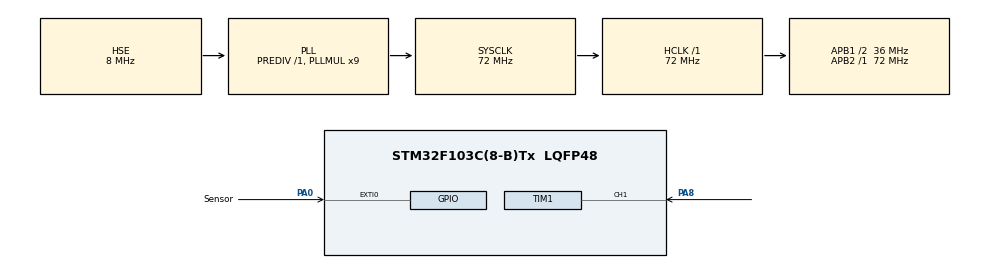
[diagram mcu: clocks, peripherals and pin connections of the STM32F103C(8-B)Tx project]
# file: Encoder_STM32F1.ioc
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Mcu.Family=STM32F1
Mcu.Name=STM32F103C(8-B)Tx
Mcu.Package=LQFP48
NVIC.EXTI0_IRQn=true\:0\:0\:true\:false\:true\:true\:true
NVIC.PriorityGroup=NVIC_PRIORITYGROUP_4
NVIC.TIM3_IRQn=true\:0\:0\:true\:false\:true\:true\:true
PA0-WKUP.GPIO_Label=Sensor
PA0-WKUP.GPIO_ModeDefaultEXTI=GPIO_MODE_IT_FALLING
PA0-WKUP.GPIO_PuPd=GPIO_PULLUP
PA0-WKUP.Signal=GPXTI0
PA13.Mode=Serial_Wire
PA13.Signal=SYS_JTMS-SWDIO
PA14.Mode=Serial_Wire
PA14.Signal=SYS_JTCK-SWCLK
PA8.Signal=S_TIM1_CH1
PD0-OSC_IN.Mode=HSE-External-Oscillator
PD0-OSC_IN.Signal=RCC_OSC_IN
PD1-OSC_OUT.Mode=HSE-External-Oscillator
PD1-OSC_OUT.Signal=RCC_OSC_OUT
ProjectManager.HeapSize=0x200
ProjectManager.StackSize=0x400
ProjectManager.TargetToolchain=MDK-ARM V5
RCC.AHBFreq_Value=72000000
RCC.APB1CLKDivider=RCC_HCLK_DIV2
RCC.APB1Freq_Value=36000000
RCC.APB1TimFreq_Value=72000000
RCC.APB2Freq_Value=72000000
RCC.APB2TimFreq_Value=72000000
RCC.HCLKFreq_Value=72000000
RCC.PLLMUL=RCC_PLL_MUL9
RCC.PLLSourceVirtual=RCC_PLLSOURCE_HSE
RCC.SYSCLKFreq_VALUE=72000000
RCC.SYSCLKSource=RCC_SYSCLKSOURCE_PLLCLK
RCC.USBFreq_Value=72000000
SH.S_TIM1_CH1.0=TIM1_CH1,PWM_Input_1
TIM1.Period=19999
TIM1.Prescaler=71
TIM3.Period=1000-1
TIM3.Prescaler=18000-1
VP_TIM1_VS_ClockSourceINT.Mode=Internal
VP_TIM3_VS_ClockSourceINT.Mode=Internal
board=custom

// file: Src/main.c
/* USER CODE BEGIN Header */
/**
  ******************************************************************************
  * @file           : main.c
  * @brief          : Main program body
  ******************************************************************************
  * @attention
  *
  * <h2><center>&copy; Copyright (c) 2020 STMicroelectronics.
  * All rights reserved.</center></h2>
  *
  * This software component is licensed by ST under BSD 3-Clause license,
  * the "License"; You may not use this file except in compliance with the
  * License. You may obtain a copy of the License at:
  *                        opensource.org/licenses/BSD-3-Clause
  *
  ******************************************************************************
  */
/* USER CODE END Header */

#include "main.h"

TIM_HandleTypeDef htim1;
TIM_HandleTypeDef htim3;

/* USER CODE BEGIN PV */
unsigned long count = 0;
double rpm;
unsigned int duty = 1000;
unsigned int dem;
/* USER CODE END PV */

void SystemClock_Config(void);
static void MX_GPIO_Init(void);
static void MX_TIM1_Init(void);
static void MX_TIM3_Init(void);

int main(void)
{

  /* MCU Configuration--------------------------------------------------------*/

  /* Reset of all peripherals, Initializes the Flash interface and the Systick. */
  HAL_Init();

  /* Configure the system clock */
  SystemClock_Config();

  /* Initialize all configured peripherals */
  MX_GPIO_Init();
  MX_TIM1_Init();
  MX_TIM3_Init();
  /* USER CODE BEGIN 2 */
	HAL_TIM_Base_Start(&htim3);
	HAL_TIM_Base_Start(&htim1);
	HAL_TIM_PWM_Start(&htim1,TIM_CHANNEL_1);
//	htim1.Instance->CCR1=1500;
	__HAL_TIM_SetCompare(&htim1,TIM_CHANNEL_1,1999);
	HAL_Delay(2000);
	__HAL_TIM_SetCompare(&htim1,TIM_CHANNEL_1,999);
	duty = 1000;
	dem = 0;
  /* USER CODE END 2 */

  /* Infinite loop */
  while (1)
  {
//		__HAL_TIM_SetCompare(&htim1,TIM_CHANNEL_1,1500);
//		htim1.Instance->CCR1=1500;
  }
}

void SystemClock_Config(void)
{
  RCC_OscInitTypeDef RCC_OscInitStruct = {0};
  RCC_ClkInitTypeDef RCC_ClkInitStruct = {0};

  /** Initializes the CPU, AHB and APB busses clocks
  */
  RCC_OscInitStruct.OscillatorType = RCC_OSCILLATORTYPE_HSE;
  RCC_OscInitStruct.HSEState = RCC_HSE_ON;
  RCC_OscInitStruct.HSEPredivValue = RCC_HSE_PREDIV_DIV1;
  RCC_OscInitStruct.HSIState = RCC_HSI_ON;
  RCC_OscInitStruct.PLL.PLLState = RCC_PLL_ON;
  RCC_OscInitStruct.PLL.PLLSource = RCC_PLLSOURCE_HSE;
  RCC_OscInitStruct.PLL.PLLMUL = RCC_PLL_MUL9;
  if (HAL_RCC_OscConfig(&RCC_OscInitStruct) != HAL_OK)
  {
    Error_Handler();
  }
  /** Initializes the CPU, AHB and APB busses clocks
  */
  RCC_ClkInitStruct.ClockType = RCC_CLOCKTYPE_HCLK|RCC_CLOCKTYPE_SYSCLK
                              |RCC_CLOCKTYPE_PCLK1|RCC_CLOCKTYPE_PCLK2;
  RCC_ClkInitStruct.SYSCLKSource = RCC_SYSCLKSOURCE_PLLCLK;
  RCC_ClkInitStruct.AHBCLKDivider = RCC_SYSCLK_DIV1;
  RCC_ClkInitStruct.APB1CLKDivider = RCC_HCLK_DIV2;
  RCC_ClkInitStruct.APB2CLKDivider = RCC_HCLK_DIV1;

  if (HAL_RCC_ClockConfig(&RCC_ClkInitStruct, FLASH_LATENCY_2) != HAL_OK)
  {
    Error_Handler();
  }
}

static void MX_TIM1_Init(void)
{

  TIM_ClockConfigTypeDef sClockSourceConfig = {0};
  TIM_SlaveConfigTypeDef sSlaveConfig = {0};
  TIM_IC_InitTypeDef sConfigIC = {0};
  TIM_MasterConfigTypeDef sMasterConfig = {0};

  htim1.Instance = TIM1;
  htim1.Init.Prescaler = 71;
  htim1.Init.CounterMode = TIM_COUNTERMODE_UP;
  htim1.Init.Period = 19999;
  htim1.Init.ClockDivision = TIM_CLOCKDIVISION_DIV1;
  htim1.Init.RepetitionCounter = 0;
  htim1.Init.AutoReloadPreload = TIM_AUTORELOAD_PRELOAD_DISABLE;
  if (HAL_TIM_Base_Init(&htim1) != HAL_OK)
  {
    Error_Handler();
  }
  sClockSourceConfig.ClockSource = TIM_CLOCKSOURCE_INTERNAL;
  if (HAL_TIM_ConfigClockSource(&htim1, &sClockSourceConfig) != HAL_OK)
  {
    Error_Handler();
  }
  if (HAL_TIM_IC_Init(&htim1) != HAL_OK)
  {
    Error_Handler();
  }
  sSlaveConfig.SlaveMode = TIM_SLAVEMODE_RESET;
  sSlaveConfig.InputTrigger = TIM_TS_TI1FP1;
  sSlaveConfig.TriggerPolarity = TIM_INPUTCHANNELPOLARITY_RISING;
  sSlaveConfig.TriggerPrescaler = TIM_ICPSC_DIV1;
  sSlaveConfig.TriggerFilter = 0;
  if (HAL_TIM_SlaveConfigSynchro(&htim1, &sSlaveConfig) != HAL_OK)
  {
    Error_Handler();
  }
  sConfigIC.ICPolarity = TIM_INPUTCHANNELPOLARITY_RISING;
  sConfigIC.ICSelection = TIM_ICSELECTION_DIRECTTI;
  sConfigIC.ICPrescaler = TIM_ICPSC_DIV1;
  sConfigIC.ICFilter = 0;
  if (HAL_TIM_IC_ConfigChannel(&htim1, &sConfigIC, TIM_CHANNEL_1) != HAL_OK)
  {
    Error_Handler();
  }
  sConfigIC.ICPolarity = TIM_INPUTCHANNELPOLARITY_FALLING;
  sConfigIC.ICSelection = TIM_ICSELECTION_INDIRECTTI;
  if (HAL_TIM_IC_ConfigChannel(&htim1, &sConfigIC, TIM_CHANNEL_2) != HAL_OK)
  {
    Error_Handler();
  }
  sMasterConfig.MasterOutputTrigger = TIM_TRGO_RESET;
  sMasterConfig.MasterSlaveMode = TIM_MASTERSLAVEMODE_DISABLE;
  if (HAL_TIMEx_MasterConfigSynchronization(&htim1, &sMasterConfig) != HAL_OK)
  {
    Error_Handler();
  }

}

static void MX_TIM3_Init(void)
{

  TIM_ClockConfigTypeDef sClockSourceConfig = {0};
  TIM_MasterConfigTypeDef sMasterConfig = {0};

  htim3.Instance = TIM3;
  htim3.Init.Prescaler = 18000-1;
  htim3.Init.CounterMode = TIM_COUNTERMODE_UP;
  htim3.Init.Period = 1000-1;
  htim3.Init.ClockDivision = TIM_CLOCKDIVISION_DIV1;
  htim3.Init.AutoReloadPreload = TIM_AUTORELOAD_PRELOAD_DISABLE;
  if (HAL_TIM_Base_Init(&htim3) != HAL_OK)
  {
    Error_Handler();
  }
  sClockSourceConfig.ClockSource = TIM_CLOCKSOURCE_INTERNAL;
  if (HAL_TIM_ConfigClockSource(&htim3, &sClockSourceConfig) != HAL_OK)
  {
    Error_Handler();
  }
  sMasterConfig.MasterOutputTrigger = TIM_TRGO_RESET;
  sMasterConfig.MasterSlaveMode = TIM_MASTERSLAVEMODE_DISABLE;
  if (HAL_TIMEx_MasterConfigSynchronization(&htim3, &sMasterConfig) != HAL_OK)
  {
    Error_Handler();
  }

}

static void MX_GPIO_Init(void)
{
  GPIO_InitTypeDef GPIO_InitStruct = {0};

  /* GPIO Ports Clock Enable */
  __HAL_RCC_GPIOD_CLK_ENABLE();
  __HAL_RCC_GPIOA_CLK_ENABLE();

  /*Configure GPIO pin : Sensor_Pin */
  GPIO_InitStruct.Pin = Sensor_Pin;
  GPIO_InitStruct.Mode = GPIO_MODE_IT_FALLING;
  GPIO_InitStruct.Pull = GPIO_PULLUP;
  HAL_GPIO_Init(Sensor_GPIO_Port, &GPIO_InitStruct);

  /* EXTI interrupt init*/
  HAL_NVIC_SetPriority(EXTI0_IRQn, 0, 0);
  HAL_NVIC_EnableIRQ(EXTI0_IRQn);

}

/* USER CODE BEGIN 4 */
	void HAL_GPIO_EXTI_Callback(uint16_t GPIO_Pin)
	{
		if (GPIO_Pin == GPIO_PIN_0)
		{
			count ++;
		}
	}

	void HAL_TIM_PeriodElapsedCallback(TIM_HandleTypeDef *htim)
	{
		if (htim->Instance == TIM3)
		{
			if (dem <10)
			{
				__HAL_TIM_SetCompare(&htim1,TIM_CHANNEL_1,duty);
				dem ++;
			}
			else
			{
				duty ++;
				dem = 0;
			}
			dem++;
			rpm = (count -1)/2/0.5/60;
			count = 0;
		}
	}
/* USER CODE END 4 */

void Error_Handler(void)
{
}

/************************ (C) COPYRIGHT STMicroelectronics *****END OF FILE****/
